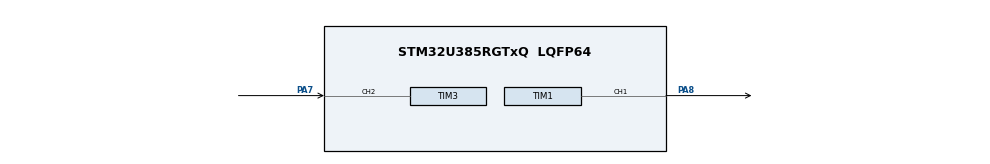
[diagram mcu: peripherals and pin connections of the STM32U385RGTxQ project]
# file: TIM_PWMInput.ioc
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CORTEX_M33_NS.userName=CORTEX_M33
Mcu.Family=STM32U3
Mcu.Name=STM32U385RGTxQ
Mcu.Package=LQFP64
NVIC.PriorityGroup=NVIC_PRIORITYGROUP_4
PA7.Signal=S_TIM3_CH2
PA8.Signal=S_TIM1_CH1
ProjectManager.HeapSize=0x200
ProjectManager.StackSize=0x400
ProjectManager.TargetToolchain=EWARM V9.20
RCC.ADCFreq_Value=96000000
RCC.AHBFreq_Value=96000000
RCC.APB1Freq_Value=96000000
RCC.APB1TimFreq_Value=96000000
RCC.APB2Freq_Value=96000000
RCC.APB2TimFreq_Value=96000000
RCC.APB3Freq_Value=96000000
RCC.CortexFreq_Value=12000000
RCC.HCLKFreq_Value=96000000
RCC.HSE_VALUE=16000000
RCC.HSI48_VALUE=48000000
RCC.HSI_VALUE=16000000
RCC.LSE_VALUE=32768
RCC.LSIDIV_VALUE=32000
RCC.MSISDIV=RCC_MSI_DIV1
RCC.MSI_VALUE=96000000
RCC.PWR_Regulator_Voltage_Scale=PWR_REGULATOR_VOLTAGE_SCALE1
RCC.SYSCLKFreq_VALUE=96000000
RCC.USBFreq_Value=96000000
SH.S_TIM1_CH1.0=TIM1_CH1,PWM Generation1 CH1
SH.S_TIM3_CH2.0=TIM3_CH2,Input_Capture2_from_TI2
SH.S_TIM3_CH2.1=TIM3_CH2,TriggerSource_TI2FP2
SH.S_TIM3_CH2.2=TIM3_CH2,Input_Capture1_from_TI2
TIM1.AutoReloadPreload=TIM_AUTORELOAD_PRELOAD_DISABLE
TIM1.AutomaticOutput=TIM_AUTOMATICOUTPUT_DISABLE
TIM1.Break2Filter=0
TIM1.Break2Polarity=TIM_BREAK2POLARITY_HIGH
TIM1.Break2State=TIM_BREAK2_DISABLE
TIM1.BreakFilter=0
TIM1.BreakPolarity=TIM_BREAKPOLARITY_HIGH
TIM1.BreakState=TIM_BREAK_DISABLE
TIM1.Channel-PWM\ Generation1\ CH1=TIM_CHANNEL_1
TIM1.ClearInputSource=TIM_CLEARINPUTSOURCE_NONE
TIM1.ClockDivision=TIM_CLOCKDIVISION_DIV1
TIM1.CounterMode=TIM_COUNTERMODE_UP
TIM1.LockLevel=TIM_LOCKLEVEL_OFF
TIM1.OC1Preload_PWM=ENABLE
TIM1.OCFastMode_PWM-PWM\ Generation1\ CH1=TIM_OCFAST_DISABLE
TIM1.OCIdleState_1=TIM_OCIDLESTATE_RESET
TIM1.OCMode_PWM-PWM\ Generation1\ CH1=TIM_OCMODE_PWM1
TIM1.OCPolarity_1=TIM_OCPOLARITY_HIGH
TIM1.OffStateIDLEMode=TIM_OSSI_DISABLE
TIM1.OffStateRunMode=TIM_OSSR_DISABLE
TIM1.PeriodNoDither=(SystemCoreClock/1)/aFrequency[0]
TIM1.Prescaler=uhPrescalerValue
TIM1.PulseNoDither_1=((SystemCoreClock/1)/aFrequency[0])/aDutyCycle[0]
TIM1.RepetitionCounter=0
TIM1.SourceBRK2COMP1=TIM_BREAKINPUTSOURCE_DISABLE
TIM1.SourceBRK2COMP2=TIM_BREAKINPUTSOURCE_DISABLE
TIM1.SourceBRK2DigInput=TIM_BREAKINPUTSOURCE_DISABLE
TIM1.SourceBRKCOMP1=TIM_BREAKINPUTSOURCE_DISABLE
TIM1.SourceBRKCOMP2=TIM_BREAKINPUTSOURCE_DISABLE
TIM1.SourceBRKDigInput=TIM_BREAKINPUTSOURCE_DISABLE
TIM1.TIM_MasterOutputTrigger=TIM_TRGO_RESET
TIM1.TIM_MasterOutputTrigger2=TIM_TRGO2_RESET
TIM1.TIM_MasterSlaveMode=TIM_MASTERSLAVEMODE_DISABLE
TIM3.AutoReloadPreload=TIM_AUTORELOAD_PRELOAD_DISABLE
TIM3.Channel-Input_Capture1_from_TI2=TIM_CHANNEL_1
TIM3.Channel-Input_Capture2_from_TI2=TIM_CHANNEL_2
TIM3.ClockDivision=TIM_CLOCKDIVISION_DIV1
TIM3.CounterMode=TIM_COUNTERMODE_UP
TIM3.ICFilter_CH2=0
TIM3.ICPolarity_CH1=TIM_INPUTCHANNELPOLARITY_FALLING
TIM3.ICPolarity_CH2=TIM_INPUTCHANNELPOLARITY_RISING
TIM3.ICPrescaler-Input_Capture1_from_TI2=TIM_ICPSC_DIV1
TIM3.ICPrescaler-Input_Capture2_from_TI2=TIM_ICPSC_DIV1
TIM3.ICSelection-Input_Capture1_from_TI2=TIM_ICSELECTION_INDIRECTTI
TIM3.ICSelection-Input_Capture2_from_TI2=TIM_ICSELECTION_DIRECTTI
TIM3.Period=0xFFFF
TIM3.PeriodNoDither=0xFFFF
TIM3.Prescaler=0x0
TIM3.TIM_MasterOutputTrigger=TIM_TRGO_RESET
TIM3.TIM_MasterSlaveMode=TIM_MASTERSLAVEMODE_DISABLE
TIM3.TIM_SlaveMode=TIM_SLAVEMODE_RESET
VP_ICACHE_VS_ICACHE.Mode=DirectMappedCache
VP_PWR_VS_DBSignals.Mode=DisableDeadBatterySignals
VP_PWR_VS_LPOM.Mode=PowerOptimisation
VP_PWR_VS_SECSignals.Mode=Security/Privilege
VP_TIM3_VS_ControllerModeReset.Mode=Reset Mode
board=custom

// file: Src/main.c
/* USER CODE BEGIN Header */
/**
  ******************************************************************************
  * @file    TIM/TIM_PWMInput/Src/main.c
  * @author  MCD Application Team
  * @brief   This example shows how to use the TIM peripheral to measure the
  *          frequency and duty cycle of an external signal.
  ******************************************************************************
  * @attention
  *
  * Copyright (c) 2024 STMicroelectronics.
  * All rights reserved.
  *
  * This software is licensed under terms that can be found in the LICENSE file
  * in the root directory of this software component.
  * If no LICENSE file comes with this software, it is provided AS-IS.
  *
  ******************************************************************************
  */
/* USER CODE END Header */
#include "main.h"

/* USER CODE BEGIN PD */
/* Number of frequencies */
#define TIM_FREQUENCIES_NB 6
#define TIM_DUTYCYCLE_NB 2
/* USER CODE END PD */

TIM_HandleTypeDef htim1;
TIM_HandleTypeDef htim3;

/* USER CODE BEGIN PV */

/* Captured Value */
__IO uint32_t            uwIC2Value = 0;
/* Duty Cycle Value */
__IO uint32_t            uwDutyCycle = 0;
/* Frequency Value */
__IO uint32_t            uwFrequency = 0;

/* Counter Prescaler value */
uint32_t uhPrescalerValue = 0;

static uint8_t iFrequency = 0;
/* Frequency index *//* Frequency table */
static uint32_t aFrequency[TIM_FREQUENCIES_NB] = {
  2000,   /*  2 kHz */
  2000,   /*  2 kHz */
  3000,   /*  3 kHz */
  3000,   /*  3 kHz */
  4000,   /*  4 kHz */
  4000,   /*  4 kHz */
};
/* Frequency index */

static uint8_t iDutyCycle = 0;
static uint32_t aDutyCycle[TIM_DUTYCYCLE_NB] = {
  2,   /*  50% */
  4,   /*  25% */
};

/* USER CODE END PV */

void SystemClock_Config(void);
static void MX_GPIO_Init(void);
static void MX_TIM1_Init(void);
static void MX_TIM3_Init(void);
static void MX_ICACHE_Init(void);

int main(void)
{

  /* USER CODE BEGIN 1 */

  /* STM32U3xx HAL library initialization:
       - Configure the Flash prefetch
       - Configure the Systick to generate an interrupt each 1 msec
       - Set NVIC Group Priority to 3
       - Low Level Initialization
     */

  /* USER CODE END 1 */

  /* MCU Configuration--------------------------------------------------------*/

  /* Reset of all peripherals, Initializes the Flash interface and the Systick. */
  HAL_Init();

  /* Configure the system clock */
  SystemClock_Config();

  /* USER CODE BEGIN SysInit */

  /* Configure LD2 */
  BSP_LED_Init(LD2);

  /* Configure User push-button in Interrupt mode */
  BSP_PB_Init(BUTTON_USER, BUTTON_MODE_EXTI);

  /* USER CODE END SysInit */

  /* Initialize all configured peripherals */
  MX_GPIO_Init();
  MX_TIM1_Init();
  MX_TIM3_Init();
  MX_ICACHE_Init();
  /* USER CODE BEGIN 2 */

 /* Start Input waveform generation */
  if (HAL_TIM_PWM_Start(&htim1, TIM_CHANNEL_1) != HAL_OK)
  {
    /* PWM Generation Error */
    Error_Handler();
  }

  /* Start the Input Capture in interrupt mode  */
  if (HAL_TIM_IC_Start_IT(&htim3, TIM_CHANNEL_2) != HAL_OK)
  {
    /* Starting Error */
    Error_Handler();
  }

  if (HAL_TIM_IC_Start_IT(&htim3, TIM_CHANNEL_1) != HAL_OK)
  {
    /* Starting Error */
    Error_Handler();
  }

  /* USER CODE END 2 */

  /* Infinite loop */
  while (1)
  {

  }
}

void SystemClock_Config(void)
{
  RCC_OscInitTypeDef RCC_OscInitStruct = {0};
  RCC_ClkInitTypeDef RCC_ClkInitStruct = {0};

  /** Enable Epod Booster
  */
  if (HAL_RCCEx_EpodBoosterClkConfig(RCC_EPODBOOSTER_SOURCE_MSIS, RCC_EPODBOOSTER_DIV1) != HAL_OK)
  {
    Error_Handler();
  }

  if (HAL_PWREx_EnableEpodBooster() != HAL_OK)
  {
    Error_Handler();
  }

  /** Configure the main internal regulator output voltage
  */
  if (HAL_PWREx_ControlVoltageScaling(PWR_REGULATOR_VOLTAGE_SCALE1) != HAL_OK)
  {
    Error_Handler();
  }

  /** Set Flash latency before increasing MSIS
  */
  __HAL_FLASH_SET_LATENCY(FLASH_LATENCY_2);

  /** Initializes the CPU, AHB and APB buses clocks
  */
  RCC_OscInitStruct.OscillatorType = RCC_OSCILLATORTYPE_MSIS;
  RCC_OscInitStruct.MSISState = RCC_MSI_ON;
  RCC_OscInitStruct.MSISSource = RCC_MSI_RC0;
  RCC_OscInitStruct.MSISDiv = RCC_MSI_DIV1;
  if (HAL_RCC_OscConfig(&RCC_OscInitStruct) != HAL_OK)
  {
    Error_Handler();
  }

  /** Initializes the CPU, AHB and APB buses clocks
  */
  RCC_ClkInitStruct.ClockType = RCC_CLOCKTYPE_HCLK|RCC_CLOCKTYPE_SYSCLK
                              |RCC_CLOCKTYPE_PCLK1|RCC_CLOCKTYPE_PCLK2
                              |RCC_CLOCKTYPE_PCLK3;
  RCC_ClkInitStruct.SYSCLKSource = RCC_SYSCLKSOURCE_MSIS;
  RCC_ClkInitStruct.AHBCLKDivider = RCC_SYSCLK_DIV1;
  RCC_ClkInitStruct.APB1CLKDivider = RCC_HCLK_DIV1;
  RCC_ClkInitStruct.APB2CLKDivider = RCC_HCLK_DIV1;
  RCC_ClkInitStruct.APB3CLKDivider = RCC_HCLK_DIV1;

  if (HAL_RCC_ClockConfig(&RCC_ClkInitStruct, FLASH_LATENCY_2) != HAL_OK)
  {
    Error_Handler();
  }
}

static void MX_ICACHE_Init(void)
{

  /** Enable instruction cache in 1-way (direct mapped cache)
  */
  if (HAL_ICACHE_ConfigAssociativityMode(ICACHE_1WAY) != HAL_OK)
  {
    Error_Handler();
  }
  if (HAL_ICACHE_Enable() != HAL_OK)
  {
    Error_Handler();
  }

}

static void MX_TIM1_Init(void)
{

  TIM_MasterConfigTypeDef sMasterConfig = {0};
  TIM_OC_InitTypeDef sConfigOC = {0};
  TIM_BreakDeadTimeConfigTypeDef sBreakDeadTimeConfig = {0};

  htim1.Instance = TIM1;
  htim1.Init.Prescaler = uhPrescalerValue;
  htim1.Init.CounterMode = TIM_COUNTERMODE_UP;
  htim1.Init.Period = (SystemCoreClock/1)/aFrequency[0];
  htim1.Init.ClockDivision = TIM_CLOCKDIVISION_DIV1;
  htim1.Init.RepetitionCounter = 0;
  htim1.Init.AutoReloadPreload = TIM_AUTORELOAD_PRELOAD_DISABLE;
  if (HAL_TIM_PWM_Init(&htim1) != HAL_OK)
  {
    Error_Handler();
  }
  sMasterConfig.MasterOutputTrigger = TIM_TRGO_RESET;
  sMasterConfig.MasterOutputTrigger2 = TIM_TRGO2_RESET;
  sMasterConfig.MasterSlaveMode = TIM_MASTERSLAVEMODE_DISABLE;
  if (HAL_TIMEx_MasterConfigSynchronization(&htim1, &sMasterConfig) != HAL_OK)
  {
    Error_Handler();
  }
  sConfigOC.OCMode = TIM_OCMODE_PWM1;
  sConfigOC.Pulse = ((SystemCoreClock/1)/aFrequency[0])/aDutyCycle[0];
  sConfigOC.OCPolarity = TIM_OCPOLARITY_HIGH;
  sConfigOC.OCNPolarity = TIM_OCNPOLARITY_HIGH;
  sConfigOC.OCFastMode = TIM_OCFAST_DISABLE;
  sConfigOC.OCIdleState = TIM_OCIDLESTATE_RESET;
  sConfigOC.OCNIdleState = TIM_OCNIDLESTATE_RESET;
  if (HAL_TIM_PWM_ConfigChannel(&htim1, &sConfigOC, TIM_CHANNEL_1) != HAL_OK)
  {
    Error_Handler();
  }
  sBreakDeadTimeConfig.OffStateRunMode = TIM_OSSR_DISABLE;
  sBreakDeadTimeConfig.OffStateIDLEMode = TIM_OSSI_DISABLE;
  sBreakDeadTimeConfig.LockLevel = TIM_LOCKLEVEL_OFF;
  sBreakDeadTimeConfig.DeadTime = 0;
  sBreakDeadTimeConfig.BreakState = TIM_BREAK_DISABLE;
  sBreakDeadTimeConfig.BreakPolarity = TIM_BREAKPOLARITY_HIGH;
  sBreakDeadTimeConfig.BreakFilter = 0;
  sBreakDeadTimeConfig.BreakAFMode = TIM_BREAK_AFMODE_INPUT;
  sBreakDeadTimeConfig.Break2State = TIM_BREAK2_DISABLE;
  sBreakDeadTimeConfig.Break2Polarity = TIM_BREAK2POLARITY_HIGH;
  sBreakDeadTimeConfig.Break2Filter = 0;
  sBreakDeadTimeConfig.Break2AFMode = TIM_BREAK_AFMODE_INPUT;
  sBreakDeadTimeConfig.AutomaticOutput = TIM_AUTOMATICOUTPUT_DISABLE;
  if (HAL_TIMEx_ConfigBreakDeadTime(&htim1, &sBreakDeadTimeConfig) != HAL_OK)
  {
    Error_Handler();
  }
  HAL_TIM_MspPostInit(&htim1);

}

static void MX_TIM3_Init(void)
{

  TIM_SlaveConfigTypeDef sSlaveConfig = {0};
  TIM_MasterConfigTypeDef sMasterConfig = {0};
  TIM_IC_InitTypeDef sConfigIC = {0};

  htim3.Instance = TIM3;
  htim3.Init.Prescaler = 0x0;
  htim3.Init.CounterMode = TIM_COUNTERMODE_UP;
  htim3.Init.Period = 0xFFFF;
  htim3.Init.ClockDivision = TIM_CLOCKDIVISION_DIV1;
  htim3.Init.AutoReloadPreload = TIM_AUTORELOAD_PRELOAD_DISABLE;
  if (HAL_TIM_Base_Init(&htim3) != HAL_OK)
  {
    Error_Handler();
  }
  if (HAL_TIM_IC_Init(&htim3) != HAL_OK)
  {
    Error_Handler();
  }
  sSlaveConfig.SlaveMode = TIM_SLAVEMODE_RESET;
  sSlaveConfig.InputTrigger = TIM_TS_TI2FP2;
  sSlaveConfig.TriggerPolarity = TIM_INPUTCHANNELPOLARITY_RISING;
  sSlaveConfig.TriggerFilter = 0;
  if (HAL_TIM_SlaveConfigSynchro(&htim3, &sSlaveConfig) != HAL_OK)
  {
    Error_Handler();
  }
  sMasterConfig.MasterOutputTrigger = TIM_TRGO_RESET;
  sMasterConfig.MasterSlaveMode = TIM_MASTERSLAVEMODE_DISABLE;
  if (HAL_TIMEx_MasterConfigSynchronization(&htim3, &sMasterConfig) != HAL_OK)
  {
    Error_Handler();
  }
  sConfigIC.ICPolarity = TIM_INPUTCHANNELPOLARITY_FALLING;
  sConfigIC.ICSelection = TIM_ICSELECTION_INDIRECTTI;
  sConfigIC.ICPrescaler = TIM_ICPSC_DIV1;
  sConfigIC.ICFilter = 0;
  if (HAL_TIM_IC_ConfigChannel(&htim3, &sConfigIC, TIM_CHANNEL_1) != HAL_OK)
  {
    Error_Handler();
  }
  sConfigIC.ICPolarity = TIM_INPUTCHANNELPOLARITY_RISING;
  sConfigIC.ICSelection = TIM_ICSELECTION_DIRECTTI;
  if (HAL_TIM_IC_ConfigChannel(&htim3, &sConfigIC, TIM_CHANNEL_2) != HAL_OK)
  {
    Error_Handler();
  }

}

static void MX_GPIO_Init(void)
{

  /* GPIO Ports Clock Enable */
  __HAL_RCC_GPIOA_CLK_ENABLE();

}

/* USER CODE BEGIN 4 */

/**
  * @brief EXTI line detection callbacks
  * @param GPIO_Pin: Specifies the pins connected EXTI line
  * @retval None
  */
void UserButton_Callback()
{
    /* Set new PWM signal frequency and duty cycle*/
    iFrequency = (iFrequency + 1) % TIM_FREQUENCIES_NB;
    iDutyCycle = (iDutyCycle + 1) % TIM_DUTYCYCLE_NB;

    /* Set the auto-reload value to have the requested frequency */
    /* Frequency = TIM1CLK / (ARR + 1) = SystemCoreClock / (ARR + 1)  */
    LL_TIM_SetAutoReload(TIM1, __LL_TIM_CALC_ARR(SystemCoreClock/1, LL_TIM_GetPrescaler(TIM1), aFrequency[iFrequency]));

    /* Set  duty cycle */
    LL_TIM_OC_SetCompareCH1(TIM1, (LL_TIM_GetAutoReload(TIM1) / aDutyCycle[iDutyCycle]));

}

/**
  * @brief  Input Capture callback in non blocking mode
  * @param  htim : TIM IC handle
  * @retval None
  */
void TimerCaptureCompare_Ch2_Callback()
{
  /* Get the Input Capture value */
  uwIC2Value = LL_TIM_IC_GetCaptureCH2(TIM3);

  if (uwIC2Value != 0)
  {
    /* Duty cycle computation */
    uwDutyCycle = (LL_TIM_IC_GetCaptureCH1(TIM3) * 100) / uwIC2Value;

    /* uwFrequency computation
    TIM3 freq  = SystemCoreClock */
    uwFrequency = SystemCoreClock  / (1*uwIC2Value);
  }
  else
  {
    uwDutyCycle = 0;
    uwFrequency = 0;
  }
}

/* USER CODE END 4 */

void Error_Handler(void)
{
  /* USER CODE BEGIN Error_Handler_Debug */
  /* User can add his own implementation to report the HAL error return state */
  /* Turn LD2 on */
  BSP_LED_On(LD2);
  while (1)
  {
  }
  /* USER CODE END Error_Handler_Debug */
}
